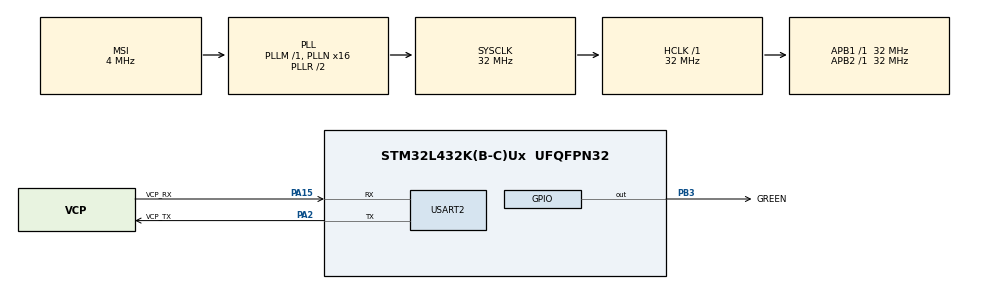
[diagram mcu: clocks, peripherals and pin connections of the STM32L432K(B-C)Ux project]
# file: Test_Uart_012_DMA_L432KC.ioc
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Dma.Request0=USART2_RX
Dma.USART2_RX.0.Direction=DMA_PERIPH_TO_MEMORY
Dma.USART2_RX.0.Instance=DMA1_Channel6
Dma.USART2_RX.0.MemDataAlignment=DMA_MDATAALIGN_BYTE
Dma.USART2_RX.0.MemInc=DMA_MINC_ENABLE
Dma.USART2_RX.0.Mode=DMA_NORMAL
Dma.USART2_RX.0.PeriphDataAlignment=DMA_PDATAALIGN_BYTE
Dma.USART2_RX.0.PeriphInc=DMA_PINC_DISABLE
Dma.USART2_RX.0.Priority=DMA_PRIORITY_LOW
Mcu.Family=STM32L4
Mcu.Name=STM32L432K(B-C)Ux
Mcu.Package=UFQFPN32
NVIC.DMA1_Channel6_IRQn=true\:0\:0\:false\:false\:true\:false\:true\:true
NVIC.PriorityGroup=NVIC_PRIORITYGROUP_4
NVIC.RTC_WKUP_IRQn=true\:0\:0\:false\:false\:true\:true\:true\:true
NVIC.TIM6_DAC_IRQn=true\:0\:0\:false\:false\:true\:true\:true\:true
NVIC.USART2_IRQn=true\:0\:0\:false\:false\:true\:true\:true\:true
PA0.GPIO_Label=MCO [High speed clock in]
PA0.Mode=HSE-External-Clock-Source-for-LittleOrca
PA0.Signal=RCC_CK_IN
PA13\ (JTMS-SWDIO).GPIO_Label=SWDIO
PA13\ (JTMS-SWDIO).Mode=Serial_Wire
PA13\ (JTMS-SWDIO).Signal=SYS_JTMS-SWDIO
PA14\ (JTCK-SWCLK).GPIO_Label=SWCLK
PA14\ (JTCK-SWCLK).Mode=Serial_Wire
PA14\ (JTCK-SWCLK).Signal=SYS_JTCK-SWCLK
PA15\ (JTDI).GPIO_Label=VCP_RX
PA15\ (JTDI).Mode=Asynchronous
PA15\ (JTDI).Signal=USART2_RX
PA2.GPIO_Label=VCP_TX
PA2.Mode=Asynchronous
PA2.Signal=USART2_TX
PB3\ (JTDO-TRACESWO).GPIO_Label=GREEN
PB3\ (JTDO-TRACESWO).Signal=GPIO_Output
PC14-OSC32_IN\ (PC14).Mode=LSE-External-Oscillator
PC14-OSC32_IN\ (PC14).Signal=RCC_OSC32_IN
PC15-OSC32_OUT\ (PC15).Mode=LSE-External-Oscillator
PC15-OSC32_OUT\ (PC15).Signal=RCC_OSC32_OUT
ProjectManager.HeapSize=0x200
ProjectManager.StackSize=0x400
ProjectManager.TargetToolchain=STM32CubeIDE
RCC.AHBFreq_Value=32000000
RCC.APB1Freq_Value=32000000
RCC.APB1TimFreq_Value=32000000
RCC.APB2Freq_Value=32000000
RCC.APB2TimFreq_Value=32000000
RCC.CortexFreq_Value=32000000
RCC.HCLKFreq_Value=32000000
RCC.HSE_VALUE=8000000
RCC.HSI16_VALUE=16000000
RCC.HSI48_VALUE=48000000
RCC.HSI_VALUE=16000000
RCC.MSI_VALUE=4000000
RCC.PLLMUL=RCC_PLLMUL_4
RCC.PLLN=16
RCC.RTCClockSelection=RCC_RTCCLKSOURCE_LSE
RCC.SYSCLKFreq_VALUE=32000000
RCC.SYSCLKSource=RCC_SYSCLKSOURCE_PLLCLK
RCC.VCOOutputFreq_Value=64000000
RTC.WakeUpClock=RTC_WAKEUPCLOCK_CK_SPRE_16BITS
RTC.WakeUpCounter=3600
TIM6.Period=5000-1
TIM6.Prescaler=32000-1
USART2.VirtualMode-Asynchronous=VM_ASYNC
VP_RTC_VS_RTC_Activate.Mode=RTC_Enabled
VP_RTC_VS_RTC_WakeUp_intern.Mode=WakeUp
VP_TIM6_VS_ClockSourceINT.Mode=Enable_Timer
board=NUCLEO-L432KC

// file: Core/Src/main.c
/* USER CODE BEGIN Header */
/**
  ******************************************************************************
  * @file           : main.c
  * @brief          : Main program body
  ******************************************************************************
  * @attention
  *
  * Copyright (c) 2022 STMicroelectronics.
  * All rights reserved.
  *
  * This software is licensed under terms that can be found in the LICENSE file
  * in the root directory of this software component.
  * If no LICENSE file comes with this software, it is provided AS-IS.
  *
  ******************************************************************************
  */
/* USER CODE END Header */
#include "main.h"

/* USER CODE BEGIN Includes */
#include <stdlib.h>
#include <stdio.h>
#include <string.h>
/* USER CODE END Includes */

/* USER CODE BEGIN PD */
#define TIM_HANDLER						htim6
#define TIM_INSTANCE					TIM6
#define UART_HANDLER					&huart2
#define UART_INSTANCE					USART2
#define UART_TX_TIMEOUT					100
#define MAX_BUFF_SIZE					100
/* USER CODE END PD */

RTC_HandleTypeDef hrtc;

TIM_HandleTypeDef htim6;

UART_HandleTypeDef huart2;
DMA_HandleTypeDef hdma_usart2_rx;

/* USER CODE BEGIN PV */
char             						rx_buff[MAX_BUFF_SIZE] ;
char             						tx_buff[MAX_BUFF_SIZE] ;
char             						dbg_buff[MAX_BUFF_SIZE] ;
uint8_t									tim_on 					= 0 ;
uint8_t									answer_from_pc			= 0 ;
const char*								hello 					= "Hello! Test_Uart_012_L432KC started\n" ;
const char*								request					= "request request" ;
const char*         					expected_answer			= "answer " ;
const char*         					dbg						= "DBG: " ;
/* USER CODE END PV */

void SystemClock_Config(void);
static void MX_GPIO_Init(void);
static void MX_DMA_Init(void);
static void MX_USART2_UART_Init(void);
static void MX_TIM6_Init(void);
static void MX_RTC_Init(void);
/* USER CODE BEGIN PFP */
uint8_t				uart_cc 					( const char* , const char* ) ;
void 				tim_init 					( void ) ;
void 				tim_start 					( void ) ;
void				clean_buff 					( char* ) ;
void 				green_toggle 				( void ) ;
HAL_StatusTypeDef 	send_string_2_uart		 	( char* , int ) ;
HAL_StatusTypeDef 	send_string_2_dbg		 	( char* , int ) ;
HAL_StatusTypeDef 	receive_uart_dma	 		( void ) ;
/* USER CODE END PFP */

int main(void)
{

  /* MCU Configuration--------------------------------------------------------*/

  /* Reset of all peripherals, Initializes the Flash interface and the Systick. */
  HAL_Init();

  /* Configure the system clock */
  SystemClock_Config();

  /* Initialize all configured peripherals */
  MX_GPIO_Init();
  MX_DMA_Init();
  MX_USART2_UART_Init();
  MX_TIM6_Init();
  MX_RTC_Init();
  /* USER CODE BEGIN 2 */
	send_string_2_dbg ( (char*) hello , strlen ( hello ) ) ;
	tim_init () ;
  /* USER CODE END 2 */

  /* Infinite loop */
  /* USER CODE BEGIN WHILE */
  while (1)
  {
	  uart_cc ( request, expected_answer ) ;
	  HAL_Delay ( 5000 ) ;
    /* USER CODE END WHILE */

  }
}

void SystemClock_Config(void)
{
  RCC_OscInitTypeDef RCC_OscInitStruct = {0};
  RCC_ClkInitTypeDef RCC_ClkInitStruct = {0};

  /** Configure the main internal regulator output voltage
  */
  if (HAL_PWREx_ControlVoltageScaling(PWR_REGULATOR_VOLTAGE_SCALE1) != HAL_OK)
  {
    Error_Handler();
  }

  /** Configure LSE Drive Capability
  */
  HAL_PWR_EnableBkUpAccess();
  __HAL_RCC_LSEDRIVE_CONFIG(RCC_LSEDRIVE_LOW);

  /** Initializes the RCC Oscillators according to the specified parameters
  * in the RCC_OscInitTypeDef structure.
  */
  RCC_OscInitStruct.OscillatorType = RCC_OSCILLATORTYPE_LSE|RCC_OSCILLATORTYPE_MSI;
  RCC_OscInitStruct.LSEState = RCC_LSE_ON;
  RCC_OscInitStruct.MSIState = RCC_MSI_ON;
  RCC_OscInitStruct.MSICalibrationValue = 0;
  RCC_OscInitStruct.MSIClockRange = RCC_MSIRANGE_6;
  RCC_OscInitStruct.PLL.PLLState = RCC_PLL_ON;
  RCC_OscInitStruct.PLL.PLLSource = RCC_PLLSOURCE_MSI;
  RCC_OscInitStruct.PLL.PLLM = 1;
  RCC_OscInitStruct.PLL.PLLN = 16;
  RCC_OscInitStruct.PLL.PLLP = RCC_PLLP_DIV7;
  RCC_OscInitStruct.PLL.PLLQ = RCC_PLLQ_DIV2;
  RCC_OscInitStruct.PLL.PLLR = RCC_PLLR_DIV2;
  if (HAL_RCC_OscConfig(&RCC_OscInitStruct) != HAL_OK)
  {
    Error_Handler();
  }

  /** Initializes the CPU, AHB and APB buses clocks
  */
  RCC_ClkInitStruct.ClockType = RCC_CLOCKTYPE_HCLK|RCC_CLOCKTYPE_SYSCLK
                              |RCC_CLOCKTYPE_PCLK1|RCC_CLOCKTYPE_PCLK2;
  RCC_ClkInitStruct.SYSCLKSource = RCC_SYSCLKSOURCE_PLLCLK;
  RCC_ClkInitStruct.AHBCLKDivider = RCC_SYSCLK_DIV1;
  RCC_ClkInitStruct.APB1CLKDivider = RCC_HCLK_DIV1;
  RCC_ClkInitStruct.APB2CLKDivider = RCC_HCLK_DIV1;

  if (HAL_RCC_ClockConfig(&RCC_ClkInitStruct, FLASH_LATENCY_1) != HAL_OK)
  {
    Error_Handler();
  }

  /** Enable MSI Auto calibration
  */
  HAL_RCCEx_EnableMSIPLLMode();
}

static void MX_RTC_Init(void)
{

  /** Initialize RTC Only
  */
  hrtc.Instance = RTC;
  hrtc.Init.HourFormat = RTC_HOURFORMAT_24;
  hrtc.Init.AsynchPrediv = 127;
  hrtc.Init.SynchPrediv = 255;
  hrtc.Init.OutPut = RTC_OUTPUT_DISABLE;
  hrtc.Init.OutPutRemap = RTC_OUTPUT_REMAP_NONE;
  hrtc.Init.OutPutPolarity = RTC_OUTPUT_POLARITY_HIGH;
  hrtc.Init.OutPutType = RTC_OUTPUT_TYPE_OPENDRAIN;
  if (HAL_RTC_Init(&hrtc) != HAL_OK)
  {
    Error_Handler();
  }

}

static void MX_TIM6_Init(void)
{

  TIM_MasterConfigTypeDef sMasterConfig = {0};

  htim6.Instance = TIM6;
  htim6.Init.Prescaler = 32000-1;
  htim6.Init.CounterMode = TIM_COUNTERMODE_UP;
  htim6.Init.Period = 5000-1;
  htim6.Init.AutoReloadPreload = TIM_AUTORELOAD_PRELOAD_DISABLE;
  if (HAL_TIM_Base_Init(&htim6) != HAL_OK)
  {
    Error_Handler();
  }
  sMasterConfig.MasterOutputTrigger = TIM_TRGO_RESET;
  sMasterConfig.MasterSlaveMode = TIM_MASTERSLAVEMODE_DISABLE;
  if (HAL_TIMEx_MasterConfigSynchronization(&htim6, &sMasterConfig) != HAL_OK)
  {
    Error_Handler();
  }

}

static void MX_USART2_UART_Init(void)
{

  huart2.Instance = USART2;
  huart2.Init.BaudRate = 115200;
  huart2.Init.WordLength = UART_WORDLENGTH_8B;
  huart2.Init.StopBits = UART_STOPBITS_1;
  huart2.Init.Parity = UART_PARITY_NONE;
  huart2.Init.Mode = UART_MODE_TX_RX;
  huart2.Init.HwFlowCtl = UART_HWCONTROL_NONE;
  huart2.Init.OverSampling = UART_OVERSAMPLING_16;
  huart2.Init.OneBitSampling = UART_ONE_BIT_SAMPLE_DISABLE;
  huart2.AdvancedInit.AdvFeatureInit = UART_ADVFEATURE_NO_INIT;
  if (HAL_UART_Init(&huart2) != HAL_OK)
  {
    Error_Handler();
  }

}

static void MX_DMA_Init(void)
{

  /* DMA controller clock enable */
  __HAL_RCC_DMA1_CLK_ENABLE();

  /* DMA interrupt init */
  /* DMA1_Channel6_IRQn interrupt configuration */
  HAL_NVIC_SetPriority(DMA1_Channel6_IRQn, 0, 0);
  HAL_NVIC_EnableIRQ(DMA1_Channel6_IRQn);

}

static void MX_GPIO_Init(void)
{
  GPIO_InitTypeDef GPIO_InitStruct = {0};

  /* GPIO Ports Clock Enable */
  __HAL_RCC_GPIOC_CLK_ENABLE();
  __HAL_RCC_GPIOA_CLK_ENABLE();
  __HAL_RCC_GPIOB_CLK_ENABLE();

  /*Configure GPIO pin Output Level */
  HAL_GPIO_WritePin(GREEN_GPIO_Port, GREEN_Pin, GPIO_PIN_RESET);

  /*Configure GPIO pin : GREEN_Pin */
  GPIO_InitStruct.Pin = GREEN_Pin;
  GPIO_InitStruct.Mode = GPIO_MODE_OUTPUT_PP;
  GPIO_InitStruct.Pull = GPIO_NOPULL;
  GPIO_InitStruct.Speed = GPIO_SPEED_FREQ_LOW;
  HAL_GPIO_Init(GREEN_GPIO_Port, &GPIO_InitStruct);

}

/* USER CODE BEGIN 4 */

uint8_t uart_cc ( const char* req , const char* ans )
{
	uint8_t try ;
	int ldbg ;

	int lm = sprintf ( tx_buff , "%s\n" , req ) ;

	for ( try = 0 ; try < 5 ; try++ )
	{
		tim_start () ;
		if ( answer_from_pc == 0 )
			if ( receive_uart_dma () != HAL_OK )
			{
				ldbg = sprintf ( dbg_buff , "%stry no. %u != HAL_OK for %s\n" , dbg , try , req ) ;
				send_string_2_dbg ( dbg_buff , ldbg ) ;
			}
		send_string_2_uart ( tx_buff , lm ) ;
		while ( tim_on )
			if ( answer_from_pc == 2 )
			{
				answer_from_pc = 0 ;
				ldbg = sprintf ( dbg_buff , "\n%stry no. %u answer_from_pc = 1 for %s\n" , dbg , try , req ) ;
				send_string_2_dbg ( dbg_buff , ldbg ) ;
				if ( strncmp ( rx_buff , ans , strlen ( ans ) ) == 0 )
				{
					send_string_2_uart ( rx_buff , strlen ( rx_buff ) ) ;
					ldbg = sprintf ( dbg_buff , "%stry no. %u success for %s\n" , dbg , try , req ) ;
					send_string_2_dbg ( dbg_buff , ldbg ) ;
					rx_buff[0] = '\0' ;
					return 1 ;
				}
				else
				{
					rx_buff[0] = '\0' ;
					break ;
				}
			}
		clean_buff ( rx_buff ) ;
	}

	ldbg = sprintf ( dbg_buff , "%s%s %s\n", dbg , (char*) ans , "not received.\n" ) ;
	send_string_2_dbg ( dbg_buff , ldbg ) ;
	return 0 ;
}

/*
uint8_t uart_cc ( const char* req , const char* ans )
{
	uint8_t try ;
	int ldbg ;

	int lm = sprintf ( tx_buff , "%s" , req ) ;

	for ( try = 0 ; try < 5 ; try++ )
	{
		tim_start () ;
		if ( receive_uart_dma () != HAL_OK )
		{
			ldbg = sprintf ( dbg_buff , "%stry no. %u receive_swarm_uart_dma () != HAL_OK for %s" , dbg , try , req ) ;
			send_string_2_dbg ( dbg_buff , ldbg ) ;
		}
		send_string_2_uart ( tx_buff , lm ) ;
		while ( tim_on )
			if ( answer_from_pc == 1 )
			{
				ldbg = sprintf ( dbg_buff , "%stry no. %u answer_from_pc = 1 for %s" , dbg , try , req ) ;
				send_string_2_dbg ( dbg_buff , ldbg ) ;
				answer_from_pc = 0 ;
				if ( strncmp ( rx_buff , ans , strlen ( ans ) ) == 0 )
				{
					send_string_2_uart ( rx_buff , strlen ( rx_buff ) ) ;
					ldbg = sprintf ( dbg_buff , "%stry no. %u success for %s" , dbg , try , req ) ;
					send_string_2_dbg ( dbg_buff , ldbg ) ;
					rx_buff[0] = '\0' ;
					return 1 ;
				}
				else
				{
					rx_buff[0] = '\0' ;
					break ;
				}
			}
	}

	ldbg = sprintf ( dbg_buff , "%s%s %s\n", dbg , (char*) ans , "not received." ) ;
	send_string_2_dbg ( dbg_buff , ldbg ) ;
	return 0 ;
}
*/
void clean_buff ( char* buff )
{
	uint8_t i ;
	for ( i = 0 ; i < MAX_BUFF_SIZE ; i++ )
		buff[i] = '\0' ;
}

void green_toggle ()
{
	HAL_GPIO_TogglePin ( GREEN_GPIO_Port , GREEN_Pin ) ;
}

HAL_StatusTypeDef send_string_2_uart ( char* s , int l )
{
	return HAL_UART_Transmit ( UART_HANDLER , (uint8_t *) s , l , UART_TX_TIMEOUT ) ;
}
HAL_StatusTypeDef send_string_2_dbg ( char* s , int l )
{
	return HAL_UART_Transmit ( UART_HANDLER , (uint8_t *) s , l , UART_TX_TIMEOUT ) ;
}

void tim_init ()
{
	__HAL_TIM_CLEAR_IT ( &TIM_HANDLER , TIM_IT_UPDATE ) ;
}
void tim_start ()
{
	HAL_TIM_Base_Start_IT ( &TIM_HANDLER ) ;
	tim_on = 1 ;
}
void HAL_TIM_PeriodElapsedCallback ( TIM_HandleTypeDef *htim )
{
	if ( htim->Instance == TIM_INSTANCE )
	{
		HAL_TIM_Base_Stop_IT ( &TIM_HANDLER ) ;
		tim_on = 0 ;
	}
}

HAL_StatusTypeDef receive_uart_dma ()
{
	HAL_StatusTypeDef r = HAL_UARTEx_ReceiveToIdle_DMA ( UART_HANDLER , (uint8_t*) rx_buff , MAX_BUFF_SIZE ) ;
	if ( r == HAL_OK )
	{
		answer_from_pc = 1 ;
		__HAL_DMA_DISABLE_IT ( &hdma_usart2_rx, DMA_IT_HT ) ; //Disable Half Transfer interrupt.
	}
	return r ;
}

void HAL_UARTEx_RxEventCallback ( UART_HandleTypeDef *huart , uint16_t Size )
{
    if ( huart->Instance == UART_INSTANCE )
    {
    	answer_from_pc = 2 ;
    	rx_buff[Size] = '\0' ;
    }
}
/* USER CODE END 4 */

void Error_Handler(void)
{
  __disable_irq();
  while (1)
  {
  }
}
